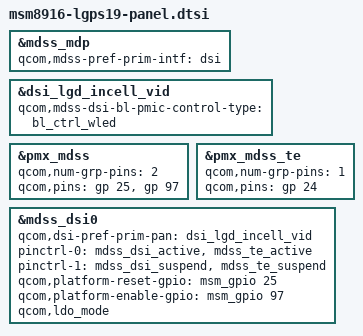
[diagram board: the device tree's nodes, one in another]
/* Copyright (c) 2013, Code Aurora Forum. All rights reserved.
 *
 * This program is free software; you can redistribute it and/or modify
 * it under the terms of the GNU General Public License version 2 and
 * only version 2 as published by the Free Software Foundation.
 *
 * This program is distributed in the hope that it will be useful,
 * but WITHOUT ANY WARRANTY; without even the implied warranty of
 * MERCHANTABILITY or FITNESS FOR A PARTICULAR PURPOSE.  See the
 * GNU General Public License for more details.
 */

#include "dsi-panel-lgd-480p-video.dtsi"

&mdss_mdp {
       qcom,mdss-pref-prim-intf = "dsi";
};

&dsi_lgd_incell_vid {
       qcom,mdss-dsi-bl-pmic-control-type = "bl_ctrl_wled";
};

&pmx_mdss {
       qcom,num-grp-pins = <2>;
       qcom,pins = <&gp 25>, <&gp 97>;
};

&pmx_mdss_te {
	qcom,num-grp-pins = <1>;
	qcom,pins = <&gp 24>;
};

&mdss_dsi0 {
       qcom,dsi-pref-prim-pan = <&dsi_lgd_incell_vid>;
       pinctrl-names = "mdss_default", "mdss_sleep";
       pinctrl-0 = <&mdss_dsi_active &mdss_te_active>;
       pinctrl-1 = <&mdss_dsi_suspend &mdss_te_suspend>;

       qcom,platform-reset-gpio = <&msm_gpio 25 0>;
       qcom,platform-enable-gpio = <&msm_gpio 97 0>;
       qcom,ldo_mode;
};
